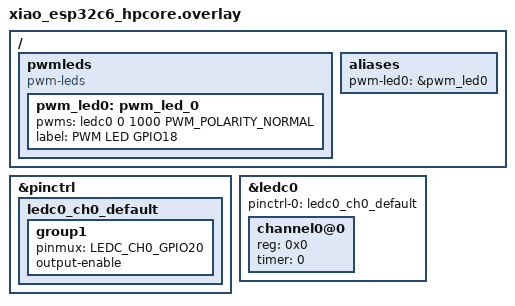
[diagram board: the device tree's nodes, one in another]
/*
 * PWM LED configuration for XIAO ESP32C6
 * Using LEDC (LED Controller) for hardware-based blinking
 */

#include <zephyr/dt-bindings/pwm/pwm.h>

&pinctrl {
	ledc0_ch0_default: ledc0_ch0_default {
		group1 {
			pinmux = <LEDC_CH0_GPIO20>;
			output-enable;
		};
	};
};

&ledc0 {
	pinctrl-0 = <&ledc0_ch0_default>;
	pinctrl-names = "default";
	status = "okay";
	#address-cells = <1>;
	#size-cells = <0>;

	channel0@0 {
		reg = <0x0>;
		timer = <0>;
	};
};

/ {
	pwmleds {
		compatible = "pwm-leds";
		
		pwm_led0: pwm_led_0 {
			pwms = <&ledc0 0 1000 PWM_POLARITY_NORMAL>;
			label = "PWM LED GPIO18";
		};
	};

	aliases {
		pwm-led0 = &pwm_led0;
	};
};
